# ESP32-C6 register map
Vendor: ESPRESSIF SYSTEMS (SHANGHAI) CO., LTD.; Series: ESP32 C-Series; File version: 12
CPU: RV32IMAC r0p0, little endian, no MPU, no FPU, 0 interrupt priority bits
Address unit: 32 bits
Registers are 32-bit, read-write, reset 0x0 unless marked. A register's access mark holds for its fields unless they carry their own. Offsets are from the block's base; [hi:lo] are bit positions; {n}, {i} and the like mark numbered series; 'fields as' and 'values as' point back to an identical list.

## APB_SARADC — SAR (Successive Approximation Register) Analog-to-Digital Converter
Base 0x6000E000
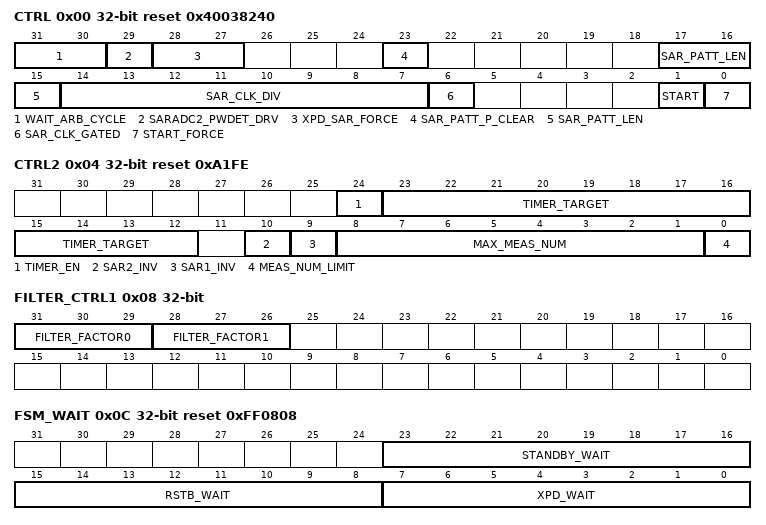
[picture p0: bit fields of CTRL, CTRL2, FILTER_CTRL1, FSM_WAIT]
0x00 CTRL reset 0x40038240 — digital saradc configure register
  [31:30] WAIT_ARB_CYCLE — wait arbit signal stable after sar_done
  [29] SARADC2_PWDET_DRV — enable saradc2 power detect driven func.
  [28:27] XPD_SAR_FORCE — force option to xpd sar blocks
  [23] SAR_PATT_P_CLEAR — clear the pointer of pattern table for DIG ADC1 CTRL
  [17:15] SAR_PATT_LEN — 0 ~ 15 means length 1 ~ 16
  [14:7] SAR_CLK_DIV — SAR clock divider
  [6] SAR_CLK_GATED — SAR clock gated
  [1] START — software enable saradc sample
  [0] START_FORCE — select software enable saradc sample
0x04 CTRL2 reset 0xA1FE — digital saradc configure register
  [24] TIMER_EN — to enable saradc timer trigger
  [23:12] TIMER_TARGET — to set saradc timer target
  [10] SAR2_INV — 1: data to DIG ADC2 CTRL is inverted, otherwise not
  [9] SAR1_INV — 1: data to DIG ADC1 CTRL is inverted, otherwise not
  [8:1] MAX_MEAS_NUM — max conversion number
  [0] MEAS_NUM_LIMIT — enable max meas num
0x08 FILTER_CTRL1 — digital saradc configure register
  [31:29] FILTER_FACTOR0 — Factor of saradc filter0
  [28:26] FILTER_FACTOR1 — Factor of saradc filter1
0x0C FSM_WAIT reset 0xFF0808 — digital saradc configure register
  [23:16] STANDBY_WAIT — saradc_standby_wait
  [15:8] RSTB_WAIT — saradc_rstb_wait
  [7:0] XPD_WAIT — saradc_xpd_wait
0x10 SAR1_STATUS ro reset 0x20000000 — digital saradc configure register
  [31:0] SAR1_STATUS — saradc1 status about data and channel
0x14 SAR2_STATUS ro reset 0x20000000 — digital saradc configure register
  [31:0] SAR2_STATUS — saradc2 status about data and channel
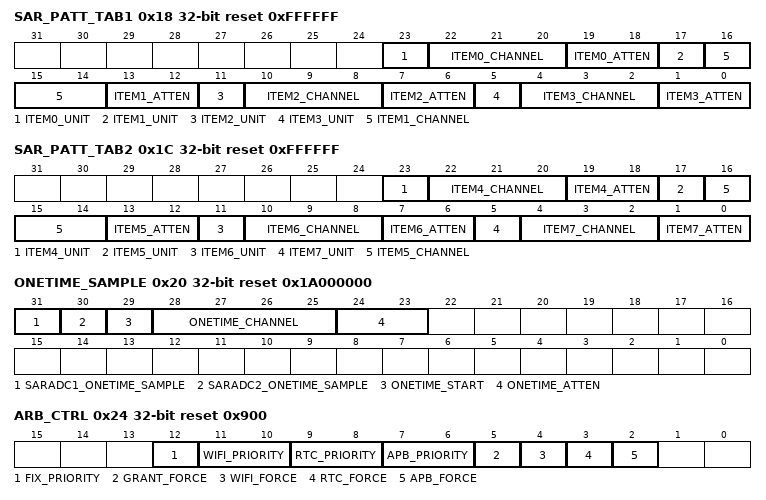
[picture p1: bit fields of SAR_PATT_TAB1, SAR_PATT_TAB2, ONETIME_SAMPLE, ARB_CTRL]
0x18 SAR_PATT_TAB1 reset 0xFFFFFF — digital saradc configure register
  [23-6n] ITEM{n}_UNIT (n=0..3)
    0=ADC1 (SAR ADC 1); 1=ADC2 (SAR ADC 2)
  [22-6n:20-6n] ITEM{n}_CHANNEL (n=0..3)
  [19-6n:18-6n] ITEM{n}_ATTEN (n=0..3)
    0=DB0 (No input attenuation, ADC can measure up to approx.); 1=DB2_5 (The input voltage of ADC will be attenuated extending the range of measurement by about 2.5 dB); 2=DB6 (The input voltage of ADC will be attenuated extending the range of measurement by about 6 dB); 3=DB12 (The input voltage of ADC will be attenuated extending the range of measurement by about 12 dB)
0x1C SAR_PATT_TAB2 reset 0xFFFFFF — digital saradc configure register
  [47-6n] ITEM{n}_UNIT (n=4..7)
    0=ADC1 (SAR ADC 1); 1=ADC2 (SAR ADC 2)
  [46-6n:44-6n] ITEM{n}_CHANNEL (n=4..7)
  [43-6n:42-6n] ITEM{n}_ATTEN (n=4..7)
    values as SAR_PATT_TAB1.ITEM0_ATTEN
0x20 ONETIME_SAMPLE reset 0x1A000000 — digital saradc configure register
  [31] SARADC1_ONETIME_SAMPLE — enable adc1 onetime sample
  [30] SARADC2_ONETIME_SAMPLE — enable adc2 onetime sample
  [29] ONETIME_START — trigger adc onetime sample
  [28:25] ONETIME_CHANNEL — configure onetime channel
  [24:23] ONETIME_ATTEN — configure onetime atten
0x24 ARB_CTRL reset 0x900 — digital saradc configure register
  [12] FIX_PRIORITY — adc2 arbiter uses fixed priority
  [11:10] WIFI_PRIORITY — Set adc2 arbiter wifi priority
  [9:8] RTC_PRIORITY — Set adc2 arbiter rtc priority
  [7:6] APB_PRIORITY — Set adc2 arbiterapb priority
  [5] GRANT_FORCE — adc2 arbiter force grant
  [4] WIFI_FORCE — adc2 arbiter force to enable wifi controller
  [3] RTC_FORCE — adc2 arbiter force to enable rtc controller
  [2] APB_FORCE — adc2 arbiter force to enableapb controller
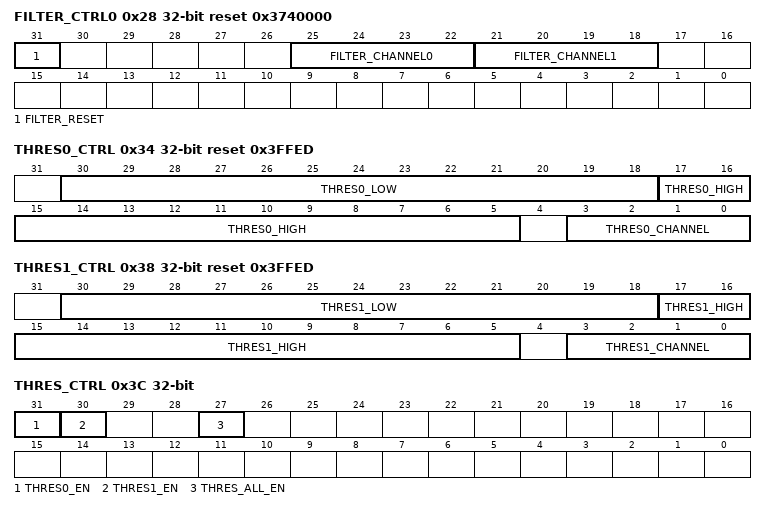
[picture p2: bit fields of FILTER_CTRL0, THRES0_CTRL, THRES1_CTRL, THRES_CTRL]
0x28 FILTER_CTRL0 reset 0x3740000 — digital saradc configure register
  [31] FILTER_RESET — enable apb_adc1_filter
  [25:22] FILTER_CHANNEL0 — configure filter0 to adc channel
  [21:18] FILTER_CHANNEL1 — configure filter1 to adc channel
0x2C SAR1DATA_STATUS ro — digital saradc configure register
  [16:0] SARADC1_DATA
0x30 SAR2DATA_STATUS ro — digital saradc configure register
  [16:0] SARADC2_DATA
0x34 THRES0_CTRL reset 0x3FFED — digital saradc configure register
  [30:18] THRES0_LOW — saradc thres0 monitor thres
  [17:5] THRES0_HIGH — saradc thres0 monitor thres
  [3:0] THRES0_CHANNEL — configure thres0 to adc channel
0x38 THRES1_CTRL reset 0x3FFED — digital saradc configure register
  [30:18] THRES1_LOW — saradc thres1 monitor thres
  [17:5] THRES1_HIGH — saradc thres1 monitor thres
  [3:0] THRES1_CHANNEL — configure thres1 to adc channel
0x3C THRES_CTRL — digital saradc configure register
  [31] THRES0_EN — enable thres0
  [30] THRES1_EN — enable thres1
  [27] THRES_ALL_EN — enable thres to all channel
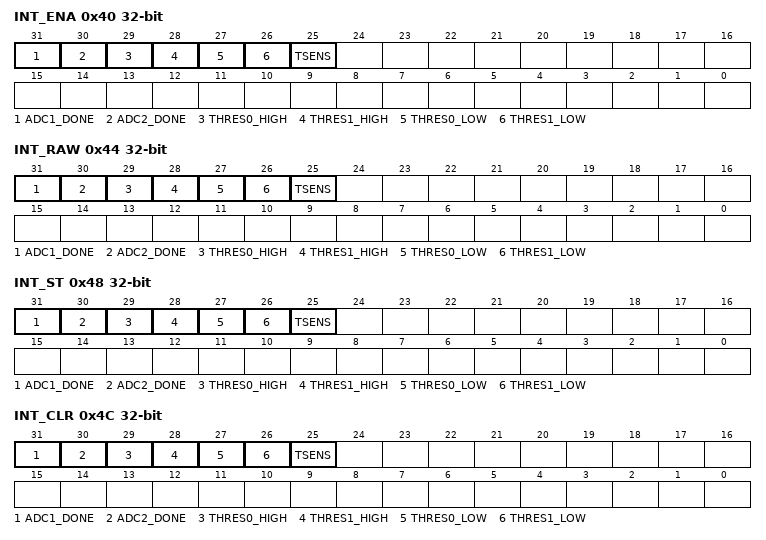
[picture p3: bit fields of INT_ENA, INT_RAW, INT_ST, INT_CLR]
0x40 INT_ENA — digital saradc int register
  [31] ADC1_DONE — saradc1 done interrupt enable
  [30] ADC2_DONE — saradc2 done interrupt enable
  [29] THRES0_HIGH — saradc thres0 high interrupt enable
  [28] THRES1_HIGH — saradc thres1 high interrupt enable
  [27] THRES0_LOW — saradc thres0 low interrupt enable
  [26] THRES1_LOW — saradc thres1 low interrupt enable
  [25] TSENS — tsens low interrupt enable
0x44 INT_RAW — digital saradc int register
  [31] ADC1_DONE — saradc1 done interrupt raw
  [30] ADC2_DONE — saradc2 done interrupt raw
  [29] THRES0_HIGH — saradc thres0 high interrupt raw
  [28] THRES1_HIGH — saradc thres1 high interrupt raw
  [27] THRES0_LOW — saradc thres0 low interrupt raw
  [26] THRES1_LOW — saradc thres1 low interrupt raw
  [25] TSENS — saradc tsens interrupt raw
0x48 INT_ST ro — digital saradc int register
  [31] ADC1_DONE — saradc1 done interrupt state
  [30] ADC2_DONE — saradc2 done interrupt state
  [29] THRES0_HIGH — saradc thres0 high interrupt state
  [28] THRES1_HIGH — saradc thres1 high interrupt state
  [27] THRES0_LOW — saradc thres0 low interrupt state
  [26] THRES1_LOW — saradc thres1 low interrupt state
  [25] TSENS — saradc tsens interrupt state
0x4C INT_CLR wo — digital saradc int register
  [31] ADC1_DONE write-1-clears — saradc1 done interrupt clear
  [30] ADC2_DONE write-1-clears — saradc2 done interrupt clear
  [29] THRES0_HIGH write-1-clears — saradc thres0 high interrupt clear
  [28] THRES1_HIGH write-1-clears — saradc thres1 high interrupt clear
  [27] THRES0_LOW write-1-clears — saradc thres0 low interrupt clear
  [26] THRES1_LOW write-1-clears — saradc thres1 low interrupt clear
  [25] TSENS write-1-clears — saradc tsens interrupt clear
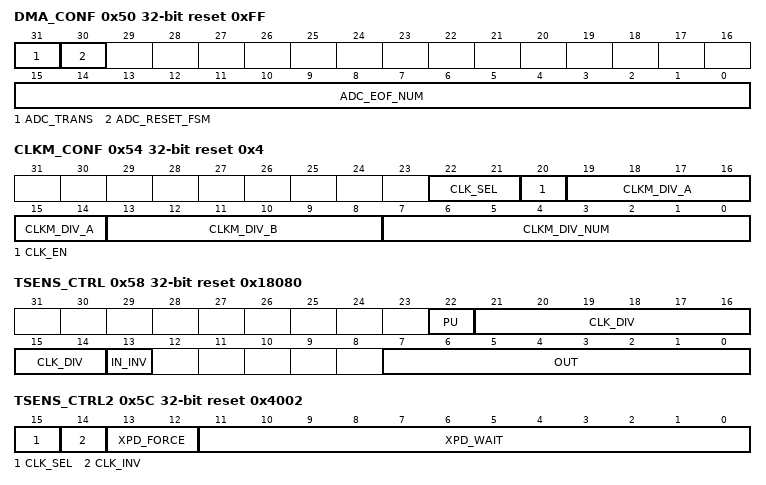
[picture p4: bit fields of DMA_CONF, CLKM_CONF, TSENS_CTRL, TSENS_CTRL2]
0x50 DMA_CONF reset 0xFF — digital saradc configure register
  [31] ADC_TRANS — enable apb_adc use spi_dma
  [30] ADC_RESET_FSM — reset_apb_adc_state
  [15:0] ADC_EOF_NUM — the dma_in_suc_eof gen when sample cnt = spi_eof_num
0x54 CLKM_CONF reset 0x4 — digital saradc configure register
  [22:21] CLK_SEL — Set this bit to enable clk_apll
  [20] CLK_EN — reg clk en
  [19:14] CLKM_DIV_A — Fractional clock divider denominator value
  [13:8] CLKM_DIV_B — Fractional clock divider numerator value
  [7:0] CLKM_DIV_NUM — Integral I2S clock divider value
0x58 TSENS_CTRL access per field reset 0x18080 — digital tsens configure register
  [22] PU rw — temperature sensor power up
  [21:14] CLK_DIV rw — temperature sensor clock divider
  [13] IN_INV rw — invert temperature sensor data
  [7:0] OUT ro — temperature sensor data out
0x5C TSENS_CTRL2 reset 0x4002 — digital tsens configure register
  [15] CLK_SEL — tsens clk select
  [14] CLK_INV — inv tsens clk
  [13:12] XPD_FORCE — force power up tsens
  [11:0] XPD_WAIT — the time that power up tsens need wait
0x60 CALI reset 0x8000 — digital saradc configure register
  [16:0] CFG — saradc cali factor
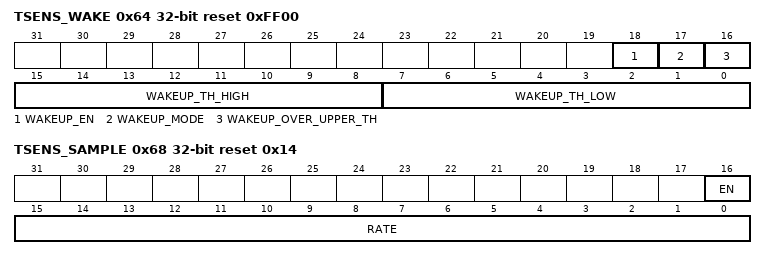
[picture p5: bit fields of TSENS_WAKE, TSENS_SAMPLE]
0x64 TSENS_WAKE access per field reset 0xFF00 — digital tsens configure register
  [18] WAKEUP_EN rw — reg_wakeup_en
  [17] WAKEUP_MODE rw — reg_wakeup_mode
  [16] WAKEUP_OVER_UPPER_TH ro — reg_wakeup_over_upper_th
  [15:8] WAKEUP_TH_HIGH rw — reg_wakeup_th_high
  [7:0] WAKEUP_TH_LOW rw — reg_wakeup_th_low
0x68 TSENS_SAMPLE reset 0x14 — digital tsens configure register
  [16] EN — HW sample en
  [15:0] RATE — HW sample rate
0x3FC CTRL_DATE — version
